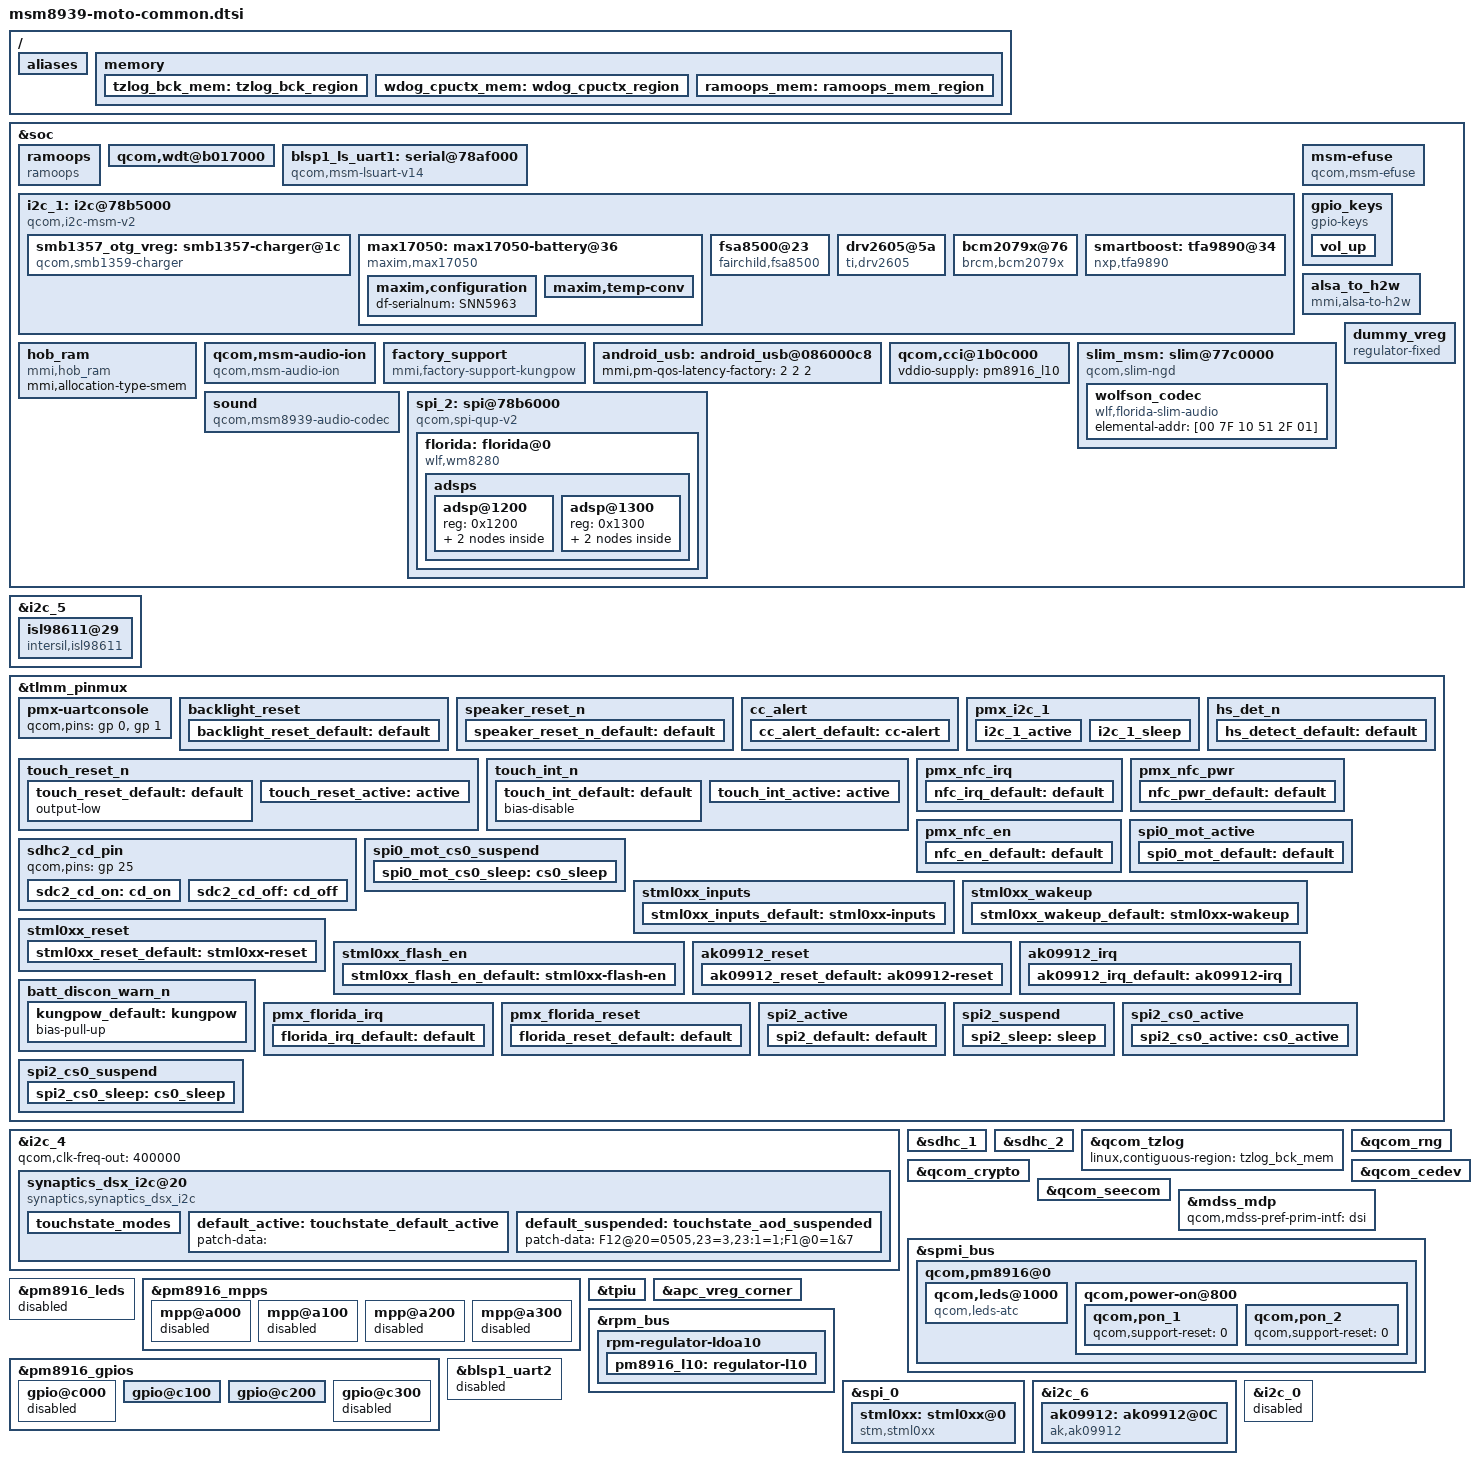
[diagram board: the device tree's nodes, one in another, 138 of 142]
/* Copyright (c) 2014, Motorola Mobility LLC. All rights reserved.
*
* This program is free software; you can redistribute it and/or modify
* it under the terms of the GNU General Public License version 2 and
* only version 2 as published by the Free Software Foundation.
*
* This program is distributed in the hope that it will be useful,
* but WITHOUT ANY WARRANTY; without even the implied warranty of
* MERCHANTABILITY or FITNESS FOR A PARTICULAR PURPOSE.  See the
* GNU General Public License for more details.
*/

#include "msm8939.dtsi"
#include "msm8939-pinctrl.dtsi"
#include "msm8939-camera-sensor-lux.dtsi"
#include "carrier-channel-ids.dtsi"
#include <moto-mem-reserve.h>

/ {
	aliases {
		serial0 = &blsp1_ls_uart1;
		i2c1 = &i2c_1;
		spi2 = &spi_2; /* Audio Codec */
	};
	memory {
		tzlog_bck_mem: tzlog_bck_region {
			linux,reserve-contiguous-region;
			linux,reserve-region;
			linux,remove-completely;
			reg = <0x0 TZLOG_BCK_BASE_8939
				0x0 TZLOG_BCK_SIZE>;
			label = "tzlog_bck_mem";
		};

		wdog_cpuctx_mem: wdog_cpuctx_region {
			linux,reserve-contiguous-region;
			linux,reserve-region;
			linux,remove-completely;
			reg = <0x0 WDOG_CPUCTX_BASE_8939
				0x0 WDOG_CPUCTX_SIZE_8939>;
			label = "wdog_cpuctx_mem";
		};

		ramoops_mem: ramoops_mem_region {
			linux,reserve-contiguous-region;
			linux,reserve-region;
			linux,remove-completely;
			reg = <0x0 0xaf000000 0x0 0x80000>;
			label = "ramoops_mem";
		};
	};
};

&soc {
	ramoops {
		compatible = "ramoops";
		status = "ok";

		android,ramoops-buffer-start = <0xaf000000>;
		android,ramoops-buffer-size = <0x80000>;
		android,ramoops-console-size = <0x40000>;
		android,ramoops-record-size = <0x3F800>;
		android,ramoops-annotate-size = <0x800>;
		android,ramoops-dump-oops = <0x1>;

		linux,contiguous-region = <&ramoops_mem>;
	};

	qcom,wdt@b017000 {
		qcom,bark-time = <22000>;
		linux,contiguous-region = <&wdog_cpuctx_mem>;
	};

	/delete-node/ serial@78af000;
	blsp1_ls_uart1: serial@78af000 {
		compatible = "qcom,msm-lsuart-v14";
		reg = <0x78af000 0x200>;
		interrupts = <0 107 0>;
		status = "ok";
		clocks = <&clock_gcc clk_gcc_blsp1_uart1_apps_clk>,
			 <&clock_gcc clk_gcc_blsp1_ahb_clk>;
		clock-names = "core_clk", "iface_clk";
		pinctrl-names = "default";
		pinctrl-0 = <&uart_console_sleep>;
	};

	i2c_1: i2c@78b5000 { /* BLSP1 QUP1 */
                compatible = "qcom,i2c-msm-v2";
                #address-cells = <1>;
                #size-cells = <0>;
                reg-names = "qup_phys_addr", "bam_phys_addr";
                reg = <0x78b5000 0x600>,
                      <0x7884000 0x23000>;
                interrupt-names = "qup_irq", "bam_irq";
                interrupts = <0 95 0>, <0 238 0>;
                clocks = <&clock_gcc clk_gcc_blsp1_ahb_clk>,
                         <&clock_gcc clk_gcc_blsp1_qup1_i2c_apps_clk>;
                clock-names = "iface_clk", "core_clk";
                qcom,clk-freq-out = <400000>;
                qcom,clk-freq-in  = <19200000>;
                pinctrl-names = "i2c_active", "i2c_sleep";
                pinctrl-0 = <&i2c_1_active>;
                pinctrl-1 = <&i2c_1_sleep>;
                qcom,noise-rjct-scl = <0>;
                qcom,noise-rjct-sda = <0>;
                qcom,bam-pipe-idx-cons = <4>;
                qcom,bam-pipe-idx-prod = <5>;
                qcom,master-id = <86>;
	};

	hob_ram {
		compatible = "mmi,hob_ram";
		mmi,allocation-type-smem;
	};

	msm-efuse {
		compatible = "qcom,msm-efuse";
	};

	/delete-node/ regulator_spk;

	qcom,msm-audio-ion {
		compatible = "qcom,msm-audio-ion";
	};

	gpio_keys {
		compatible = "gpio-keys";
		input-name = "gpio-keys";
		pinctrl-names = "tlmm_gpio_key_active","tlmm_gpio_key_suspend";
		pinctrl-0 = <&gpio_key_active>;
		pinctrl-1 = <&gpio_key_suspend>;

		vol_up {
			label = "volume_up";
			gpios = <&msm_gpio 107 0x1>;
			linux,input-type = <1>;
			linux,code = <115>;
			gpio-key,wakeup;
			debounce-interval = <15>;
		};
	};

	factory_support {
		compatible = "mmi,factory-support-kungpow";
		gpios = <&msm_gpio 89 0x0>, /* GPIOF_OUT_INIT_LOW */
			<&msm_gpio 91 0x1>, /* GPIOF_IN */
			<&msm_gpio 93 0x1>; /* GPIOF_IN */
		gpio-names = "factory_kill_disable",
			"factory_cable_detect",
			"factory_warn";
		pinctrl-names = "default";
		pinctrl-0 = <&kungpow_default>;
	};

	android_usb: android_usb@086000c8 {
		mmi,pm-qos-latency-factory = <2 2 2>;
        };

	qcom,cci@1b0c000 {
		vddio-supply = <&pm8916_l10>;
	};

	alsa_to_h2w {
		compatible = "mmi,alsa-to-h2w";
	};

	/delete-node/ slim@77c0000;
	slim_msm: slim@77c0000 {
		cell-index = <1>;
		compatible = "qcom,slim-ngd";
		reg = <0x77c0000 0x2C000>,
		      <0x7784000 0x2A000>;
		reg-names = "slimbus_physical", "slimbus_bam_physical";
		interrupts = <0 163 0>, <0 180 0>;
		interrupt-names = "slimbus_irq", "slimbus_bam_irq";
		qcom,apps-ch-pipes = <0x600000>;
		qcom,ea-pc = <0x140>;

		wolfson_codec {
			compatible = "wlf,florida-slim-audio";
			elemental-addr = [00 7F 10 51 2F 01];
		};
	};

	dummy_vreg: dummy_vreg {
		compatible = "regulator-fixed";
		status = "ok";
		regulator-name = "dummy_vreg";
		regulator-always-on;
	};

	sound {
		compatible = "qcom,msm8939-audio-codec";
		qcom,model = "msm8939-florida-snd-card";
		qcom,tfa9890-earpiece-gpio = <&msm_gpio 89 0>;
		qcom,tfa9890-stereo;
		qcom,cdc-us-euro-gpios = <&msm_gpio 120 0>;
		qcom,headset-jack-type-NC;

		pinctrl-names = "cdc_slim_lines_act", "cdc_slim_lines_sus";
		pinctrl-0 = <&cdc_slim_lines_act>;
		pinctrl-1 = <&cdc_slim_lines_sus>;

		asoc-platform = <&pcm0>, <&pcm1>, <&voip>, <&voice>,
				<&loopback>, <&compress>, <&hostless>,
				<&afe>, <&lsm>, <&routing>, <&lpa>, <&florida>;
		asoc-platform-names = "msm-pcm-dsp.0", "msm-pcm-dsp.1",
				"msm-voip-dsp", "msm-pcm-voice", "msm-pcm-loopback",
				"msm-compress-dsp", "msm-pcm-hostless", "msm-pcm-afe",
				"msm-lsm-client", "msm-pcm-routing", "msm-pcm-lpa",
				"florida-codec";
		asoc-cpu = <&dai_hdmi>, <&dai_mi2s0>, <&dai_mi2s1>,
				<&dai_mi2s2>, <&dai_mi2s3>, <&sb_0_rx>, <&sb_0_tx>,
				<&sb_1_rx>, <&sb_1_tx>, <&sb_3_rx>, <&sb_3_tx>,
				<&sb_4_rx>, <&sb_4_tx>, <&sb_5_tx>, <&bt_sco_rx>,
				<&bt_sco_tx>, <&int_fm_rx>, <&int_fm_tx>, <&afe_pcm_rx>,
				<&afe_pcm_tx>, <&afe_proxy_rx>, <&afe_proxy_tx>,
				<&incall_record_rx>, <&incall_record_tx>, <&incall_music_rx>,
				<&incall_music_2_rx>;
		asoc-cpu-names = "msm-dai-q6-hdmi.8", "msm-dai-q6-mi2s.0",
				"msm-dai-q6-mi2s.1", "msm-dai-q6-mi2s.2",
				"msm-dai-q6-mi2s.3", "msm-dai-q6-dev.16384",
				"msm-dai-q6-dev.16385", "msm-dai-q6-dev.16386",
				"msm-dai-q6-dev.16387", "msm-dai-q6-dev.16390",
				"msm-dai-q6-dev.16391", "msm-dai-q6-dev.16392",
				"msm-dai-q6-dev.16393", "msm-dai-q6-dev.16395",
				"msm-dai-q6-dev.12288", "msm-dai-q6-dev.12289",
				"msm-dai-q6-dev.12292", "msm-dai-q6-dev.12293",
				"msm-dai-q6-dev.224", "msm-dai-q6-dev.225",
				"msm-dai-q6-dev.241", "msm-dai-q6-dev.240",
				"msm-dai-q6-dev.32771", "msm-dai-q6-dev.32772",
				"msm-dai-q6-dev.32773", "msm-dai-q6-dev.32770";
		asoc-codec = <&stub_codec>;
		asoc-codec-names = "msm-stub-codec.1";
	};

	spi_2: spi@78b6000 { /* BLSP1 QUP2 */
		compatible = "qcom,spi-qup-v2";
		#address-cells = <1>;
		#size-cells = <0>;
		reg-names = "spi_physical", "spi_bam_physical";
		reg = <0x78b6000 0x600>,
			<0x7884000 0x23000>;
		interrupt-names = "spi_irq", "spi_bam_irq";
		interrupts = <0 96 0>, <0 238 0>;
		spi-max-frequency = <48000000>;
		pinctrl-names = "default", "sleep", "cs_default";

		pinctrl-0 = <&spi2_default &spi2_cs0_active>;
		pinctrl-1 = <&spi2_sleep &spi2_cs0_sleep>;

		clocks = <&clock_gcc clk_gcc_blsp1_ahb_clk>,
			<&clock_gcc clk_gcc_blsp1_qup2_spi_apps_clk>;
		clock-names = "iface_clk", "core_clk";
		qcom,infinite-mode = <0>;
		qcom,force-cs;
		qcom,use-bam;
		qcom,use-pinctrl;
		qcom,ver-reg-exists;
		qcom,bam-consumer-pipe-index = <6>;
		qcom,bam-producer-pipe-index = <7>;
		qcom,master-id = <86>;
	};
};

&i2c_5 {
	isl98611@29 {
		compatible = "intersil,isl98611";
		reg = <0x29>;
		status = "okay";
		linux,name = "wled:backlight";
		linux,default-trigger = "bkl-trigger";
		intersil,default-on;
		intersil,vn = <20>;
		intersil,vp = <20>;
		intersil,pfm-value = <0x86>;
		intersil,no-reset;
		intersil,init-level = <255>;
		intersil,dimm-threshold = <0x02>;
		pinctrl-names = "default";
		pinctrl-0 = <&backlight_reset_default>;
	};
};

&tlmm_pinmux {
	pmx-uartconsole {
		qcom,pins = <&gp 0>, <&gp 1>;
	};

	backlight_reset {
		qcom,pins = <&gp 101>;
		qcom,num-grp-pins = <1>;
		qcom,pin-func = <0>;
		label = "backlight_reset";
		backlight_reset_default: default {
			drive-strength = <2>;
			output-high;
		};
	};

	speaker_reset_n {
		qcom,pins = <&gp 37>;
		qcom,num-grp-pins = <1>;
		qcom,pin-func = <0>;
		label = "speaker_reset_n";
		speaker_reset_n_default: default {
			drive-strength = <2>;
			output-high;
		};
	};

	cc_alert {
		qcom,pins = <&gp 49>;
		qcom,num-grp-pins = <1>;
		qcom,pin-func = <0>;
		label = "cc-alert";

		cc_alert_default: cc-alert {
			drive-strength = <2>;
			bias-pull-up;
		};
	};

	pmx_i2c_1 {
		/* CLK, DATA */
		qcom,pins = <&gp 3>, <&gp 2>;
		qcom,num-grp-pins = <2>;
		qcom,pin-func = <3>;
		label = "pmx_i2c_1";

		i2c_1_active: i2c_1_active {
			drive-strength = <2>; /* 2 MA */
			bias-disable;         /* No PULL */
		};

		i2c_1_sleep: i2c_1_sleep {
			drive-strength = <2>; /* 2 MA */
			bias-disable;         /* No PULL */
		};
	};

	/delete-node/ pmx_rd_nfc_int;
	/delete-node/ pmx_nfc_reset;

	touch_reset_n {
		qcom,pins = <&gp 20>;
		qcom,num-grp-pins = <1>;
		qcom,pin-func = <0>;
		label = "touch-reset";

		touch_reset_default: default {
			output-low;
		};

		touch_reset_active: active {
			drive-strength = <2>;
			bias-pull-up; /* pull-up */
		};
	};

	touch_int_n {
		qcom,pins = <&gp 21>;
		qcom,num-grp-pins = <1>;
		qcom,pin-func = <0>;
		label = "touch-int";

		touch_int_default: default {
			bias-disable;
		};

		touch_int_active: active {
			drive-strength = <2>;
			bias-pull-up; /* pull-up */
		};
	};

	hs_det_n {
		qcom,pins = <&gp 69>;
		qcom,num-grp-pins = <1>;
		qcom,pin-func = <0>;
		label = "hs-detect-int";

		hs_detect_default: default {
			drive-strength = <2>;
			bias-pull-up;
		};
	};

	pmx_nfc_irq {
		qcom,pins = <&gp 97>;
		qcom,num-grp-pins = <1>;
		qcom,pin-func = <0>;
		label = "nfc_irq";

		nfc_irq_default: default {
			bias-pull-down;
			drive-strength = <2>;
		};
	};

	pmx_nfc_pwr {
		qcom,pins = <&gp 81>;
		qcom,num-grp-pins = <1>;
		qcom,pin-func = <0>;
		label = "nfc_pwr";

		nfc_pwr_default: default {
			bias-pull-down;
			output-low;
			drive-strength = <2>;
		};
	};

	pmx_nfc_en {
		qcom,pins = <&gp 95>;
		qcom,num-grp-pins = <1>;
		qcom,pin-func = <0>;
		label = "nfc_en";

		nfc_en_default: default {
			bias-pull-down;
			output-low;
			drive-strength = <2>;
		};
	};

	sdhc2_cd_pin {
		qcom,pins = <&gp 25>;
		sdc2_cd_on: cd_on {
			drive-strength = <2>;
			bias-disable;
		};
		sdc2_cd_off: cd_off {
			drive-strength = <2>;
			bias-disable;
		};
	};

	spi0_mot_active {
		/* MOSI, MISO, CLK */
		qcom,pins = <&gp 8>, <&gp 9>, <&gp 11>;
		qcom,num-grp-pins = <3>;
		qcom,pin-func = <1>;
		label = "spi0-mot-active";
		/* active state */
		spi0_mot_default: default {
			drive-strength = <2>; /* 2 MA */
			bias-disable = <0>; /* No PULL */
		};
	};

	spi0_mot_cs0_suspend {
		/* CS */
		qcom,pins = <&gp 10>;
		qcom,num-grp-pins = <1>;
		qcom,pin-func = <0>;
		label = "spi0-mot-cs0-suspend";
		spi0_mot_cs0_sleep: cs0_sleep {
			drive-strength = <2>;
			bias-disable = <0>;
			output-high;
		};
	};

	/* IRQ, WakeIRQ, SPI Data Ack, SPI Ready for Receive */
	stml0xx_inputs {
		qcom,pins = <&gp 51>, <&gp 52>, <&gp 38>, <&gp 13>;
		qcom,num-grp-pins = <4>;
		qcom,pin-func = <0>;
		label = "stml0xx-inputs";

		stml0xx_inputs_default: stml0xx-inputs {
			bias-disable;         /* no pull */
			drive-strength = <2>;
		};
	};

	stml0xx_wakeup {
		qcom,pins = <&gp 116>;
		qcom,num-grp-pins = <1>;
		qcom,pin-func = <0>;
		label = "stml0xx-wakeup";

		stml0xx_wakeup_default: stml0xx-wakeup {
			bias-disable;         /* no pull */
			drive-strength = <2>;
			output-high;
		};
	};

	stml0xx_reset {
		qcom,pins = <&gp 120>;
		qcom,num-grp-pins = <1>;
		qcom,pin-func = <0>;
		label = "stml0xx-reset";

		stml0xx_reset_default: stml0xx-reset {
			bias-disable;         /* no pull */
			drive-strength = <2>;
			output-high;
		};
	};

	stml0xx_flash_en {
		qcom,pins = <&gp 121>;
		qcom,num-grp-pins = <1>;
		qcom,pin-func = <0>;
		label = "stml0xx-flash-en";

		stml0xx_flash_en_default: stml0xx-flash-en {
			bias-disable;         /* no pull */
			drive-strength = <2>;
			output-low;
		};
	};

	ak09912_reset {
		qcom,pins = <&gp 90>;
		qcom,num-grp-pins = <1>;
		qcom,pin-func = <0>;
		label = "ak09912-reset";

		ak09912_reset_default: ak09912-reset {
			bias-disable;
			drive-strength = <2>;
			output-high;
		};
	};

	ak09912_irq {
		qcom,pins = <&gp 50>;
		qcom,num-grp-pins = <1>;
		qcom,pin-func = <0>;
		label = "ak09912-irq";

		ak09912_irq_default: ak09912-irq {
			bias-disable;
			drive-strength = <2>;
		};
	};

	batt_discon_warn_n {
		qcom,pins = <&gp 93>;
		qcom,num-grp-pins = <1>;
		qcom,pin-func = <0>;
		label = "batt-discon-warn-n";

		kungpow_default: kungpow {
			bias-pull-up; /* pull-up */
		};
	};

	pmx_florida_irq {
		qcom,pins = <&gp 98>;
		qcom,num-grp-pins = <1>;
		qcom,pin-func = <0>;
		label = "florida_irq";
		florida_irq_default: default {
			bias-disable;
			drive-strength = <2>;
		};
	};

	pmx_florida_reset {
		qcom,pins = <&gp 31>;
		qcom,num-grp-pins = <1>;
		qcom,pin-func = <0>;
		label = "florida_reset";
		florida_reset_default: default {
			output-high;
			bias-pull-up;
			drive-strength = <2>;
		};
	};

	spi2_active {
		/* MOSI, MISO, CLK */
		qcom,pins = <&gp 4>, <&gp 5>, <&gp 7>;
		qcom,num-grp-pins = <3>;
		qcom,pin-func = <1>;
		label = "spi2-active";
		/* active state */
		 spi2_default: default {
			bias-pull-up;
			drive-strength = <6>; /* 6 MA */
		};
	};

	spi2_suspend {
		/* MOSI, MISO, CLK */
		qcom,pins = <&gp 4>, <&gp 5>, <&gp 7>;
		qcom,num-grp-pins = <3>;
		qcom,pin-func = <1>;
		label = "spi2-suspend";
		/* suspended state */
		spi2_sleep: sleep {
			bias-pull-up;
			drive-strength = <6>; /* 6 MA */
		};
	};

	spi2_cs0_active {
		/* CS */
		qcom,pins = <&gp 6>;
		qcom,num-grp-pins = <1>;
		qcom,pin-func = <1>;
		label = "spi2-cs0-active";
		spi2_cs0_active: cs0_active {
			bias-pull-up;
			drive-strength = <6>; /* 6 MA */
		};
	};

	spi2_cs0_suspend {
		/* CS */
		qcom,pins = <&gp 6>;
		qcom,num-grp-pins = <1>;
		qcom,pin-func = <1>;
		label = "spi2-cs0-suspend";
		spi2_cs0_sleep: cs0_sleep {
			bias-pull-up;
			drive-strength = <6>; /* 6 MA */
		};
	};
};

&i2c_4 {
	qcom,clk-freq-out = <400000>;

	synaptics_dsx_i2c@20 {
		compatible = "synaptics,synaptics_dsx_i2c";
		reg = <0x20>;
		interrupt-parent = <&msm_gpio>;
		interrupts = <21 0>;
		gpios = <&msm_gpio 21 0>, /* IRQ */
			<&msm_gpio 20 0>; /* RESET */
		synaptics,gpio-config;
		pinctrl-names = "default", "active";
		pinctrl-0 = <&touch_reset_active &touch_int_default>;
		pinctrl-1 = <&touch_reset_active &touch_int_active>;
		touchstate_modes {
			touchmode-default = <&default_active &default_suspended>;
		};
		default_active: touchstate_default_active {
			patch-data = "";
		};
		default_suspended: touchstate_aod_suspended {
			patch-data = "F12@20=0505,23=3,23:1=1;F1@0=1&7";
		};
	};
};

&sdhc_1 {
	vdd-supply = <&pm8916_l8>;
	qcom,vdd-voltage-level = <2900000 2900000>;
	qcom,vdd-current-level = <200 400000>;

	vdd-io-supply = <&pm8916_l5>;
	qcom,vdd-io-always-on;
	qcom,vdd-io-lpm-sup;
	qcom,vdd-io-voltage-level = <1800000 1800000>;
	qcom,vdd-io-current-level = <200 60000>;

	pinctrl-names = "active", "sleep";
	pinctrl-0 = <&sdc1_clk_on &sdc1_cmd_on &sdc1_data_on>;
	pinctrl-1 = <&sdc1_clk_off &sdc1_cmd_off &sdc1_data_off>;

	qcom,nonremovable;
	qcom,emmc;

	status = "ok";
};

&sdhc_2 {
	vdd-supply = <&pm8916_l11>;
	qcom,vdd-voltage-level = <2800000 2950000>;
	qcom,vdd-current-level = <15000 400000>;

	vdd-io-supply = <&pm8916_l12>;
	qcom,vdd-io-voltage-level = <1800000 2950000>;
	qcom,vdd-io-current-level = <200 50000>;

	pinctrl-names = "active", "sleep";
	pinctrl-0 = <&sdc2_clk_on &sdc2_cmd_on &sdc2_data_on &sdc2_cd_on>;
	pinctrl-1 = <&sdc2_clk_off &sdc2_cmd_off &sdc2_data_off &sdc2_cd_off>;

	#address-cells = <0>;
	interrupt-parent = <&sdhc_2>;
	interrupts = <0 1 2>;
	#interrupt-cells = <1>;
	interrupt-map-mask = <0xffffffff>;
	interrupt-map = <0 &intc 0 125 0
			1 &intc 0 221 0
			2 &msm_gpio 25 0>;
	interrupt-names = "hc_irq", "pwr_irq", "status_irq";
	cd-gpios = <&msm_gpio 25 0x0>;

	qcom,sd;

	status = "ok";
};

&qcom_tzlog {
	status = "okay";
	linux,contiguous-region = <&tzlog_bck_mem>;
};

&qcom_rng {
	status = "okay";
};

&qcom_crypto {
	status = "okay";
};

&qcom_cedev {
	status = "okay";
};

&qcom_seecom {
	status = "okay";
};

&mdss_mdp {
	qcom,mdss-pref-prim-intf = "dsi";
};

&spmi_bus {
	qcom,pm8916@0 {
		qcom,leds@1000 {
			reg = <0x1000 0x100>;
			compatible = "qcom,leds-atc";
			linux,name = "charging";
			qcom,ctrl-reg = <0x4D>;
		};

		qcom,power-on@800 {
			qcom,pon_1 {
				qcom,support-reset = <0>;
			};
			qcom,pon_2 {
				qcom,support-reset = <0>;
			};
		};
	};

};

&pm8916_leds {
	status = "disabled";
};

&pm8916_mpps {
	mpp@a000 { /* MPP 1 */
		status = "disabled";
	};

	mpp@a100 { /* MPP 2 */
		status = "disabled";
	};

	mpp@a200 { /* MPP 3 */
		status = "disabled";
	};

	mpp@a300 { /* MPP 4 */
		status = "disabled";
	};
};

&pm8916_gpios {
	gpio@c000 { /* GPIO 1 */
		/* Battery UICC Alarm */
		status = "disabled";
	};

	gpio@c100 { /* GPIO 2 */
		/* NFC_CLK_REQ */
		qcom,mode = <0>; /* QPNP_PIN_MODE_DIG_IN */
		qcom,pull = <5>; /* QPNP_PIN_PULL_NO */
		qcom,vin-sel = <2>; /* QPNP_PIN_VIN2 */
		qcom,src-sel = <2>; /* QPNP_PIN_SEL_FUNC_1 */
		qcom,master-en = <1>;
	};

	gpio@c200 { /* GPIO 3 */
		/* WM5110LDO_EN */
		status = "okay";
		qcom,mode = <1>;	/* QPNP_PIN_MODE_DIG_OUT */
		qcom,pull = <5>;	/* QPNP_PIN_PULL_NO */
		qcom,vin-sel = <2>;	/* QPNP_PIN_VIN2 */
		qcom,src-sel = <0>;	/* QPNP_PIN_SEL_FUNC_CONSTANT */
		qcom,master-en = <1>;
		qcom,invert = <1>;	/* Invert to get output HIGH */
	};

	gpio@c300 { /* GPIO 4 */
		/* External regulator control for APC */
		status = "disabled";
	};
};

/* CoreSight */
&tpiu {
	pinctrl-names = "sdcard", "trace", "swduart",
			"swdtrc", "jtag", "spmi";
	/* NIDnT */
	pinctrl-0 = <&qdsd_clk_sdcard &qdsd_cmd_sdcard
		     &qdsd_data0_sdcard &qdsd_data1_sdcard
		     &qdsd_data2_sdcard &qdsd_data3_sdcard>;
	pinctrl-1 = <&qdsd_clk_trace &qdsd_cmd_trace
		     &qdsd_data0_trace &qdsd_data1_trace
		     &qdsd_data2_trace &qdsd_data3_trace>;
	pinctrl-2 = <&qdsd_cmd_swduart &qdsd_data0_swduart
		     &qdsd_data1_swduart &qdsd_data2_swduart
		     &qdsd_data3_swduart>;
	pinctrl-3 = <&qdsd_clk_swdtrc &qdsd_cmd_swdtrc
		     &qdsd_data0_swdtrc &qdsd_data1_swdtrc
		     &qdsd_data2_swdtrc &qdsd_data3_swdtrc>;
	pinctrl-4 = <&qdsd_cmd_jtag &qdsd_data0_jtag
		     &qdsd_data1_jtag &qdsd_data2_jtag
		     &qdsd_data3_jtag>;
	pinctrl-5 = <&qdsd_clk_spmi &qdsd_cmd_spmi
		     &qdsd_data0_spmi &qdsd_data3_spmi>;
};

&apc_vreg_corner {
		qcom,cpr-up-threshold = <0>;
		qcom,cpr-down-threshold = <8>;
};

&i2c_1 {
        smb1357_otg_vreg: smb1357-charger@1c {
                compatible = "qcom,smb1359-charger";
                reg = <0x1c>;

                interrupt-parent = <&msm_gpio>;
		interrupts = <62 8>;
		pinctrl-names = "default";
		pinctrl-0 = <&smb_int_default>;
                qcom,smb135x-adc_tm = <&pm8916_adc_tm>;
                qcom,smb135x-vadc = <&pm8916_vadc>;
                qcom,float-voltage-mv = <4400>;
                qcom,charging-timeout = <1536>;
                qcom,recharge-thresh-mv = <200>;
                qcom,iterm-disabled;
                qcom,aicl-disabled;
                qcom,ir-comp-mv = <100>;
                regulator-name = "smb1357_otg_vreg";
                qcom,soft-vfloat-comp-disabled;
                /* therm-bias-supply = <&pma8084_lvs2>; */
                qcom,thermal-mitigation = <2500>, <2400>, <2300>, <2100>,
                                          <2000>, <1910>, <1800>, <1600>,
                                          <1500>, <1400>, <1200>, <1100>,
                                          <1000>, <900>, <700>, <600>,
                                          <500>, <400>, <300>;
                qcom,bms-psy-name = "max170xx_battery";
                qcom,max-batt-curr-ma = <2600>;
                qcom,ext-temp-volt-mv = <4000>;
                qcom,ext-temp-soc = <65>;
                qcom,low-voltage-uv = <3200000>;
                qcom,max-voltage-uv = <4350000>;
		qcom,stepchg-voltage-mv = <4100>;
		qcom,stepchg-taper-ma = <1800>;
        };

	max17050: max17050-battery@36 {
		compatible = "maxim,max17050";
		reg = <0x36>;
		maxim,rsns-microohm = <10000>;

		interrupt-parent = <&msm_gpio>;
		interrupts = <49 0x0>;
		gpios = <&msm_gpio 49 0x11>; /* GPIOF_DIR_IN|GPIOF_EXPORT */
		gpio-names = "cc-alert";

		maxim,enable_por_init;
		maxim,batt_undervoltage_zero_soc;
		maxim,batt-psy-name = "battery";
		maxim,warm-temp-c = <45>;
		maxim,hot-temp-c = <60>;
		maxim,cool-temp-c = <0>;
		maxim,cold-temp-c = <(-20)>;

		maxim,valrt-threshold = <0xffa0>; /* Vmin 3.2V */
		maxim,df-read-battsn;

		pinctrl-names = "default";
		pinctrl-0 = <&cc_alert_default>;

		maxim,configuration {
			df-serialnum    = "SNN5963";

			/include/ "batterydata-fl40-lg.dtsi"
		};

		maxim,temp-conv {
			start   = /bits/ 16 <(-20)>;    /* in degrees C */
			result  = /bits/ 16 <
				/* 1/10th C "real" temps corresponding start, start + 1, etc. fuel gauge temps in C */
				(-302) (-271) (-246) (-222) (-202) (-180) (-162) (-147) (-129) (-114)   /* -20 C ... -11 C */
				(-101) (-86)  (-72)  (-59)  (-48)  (-35)  (-23)  (-12)  (-2)   10       /* -10 C ... -1  C */
				22     32     42     51     62     72     82     91     99     110      /*  0  C ...  9  C */
				120    129    138    146    156    165    175    184    192    200      /*  10 C ...  19 C */
				210    220    230    238    247    256    266    275    285    294      /*  20 C ...  29 C */
				303    313    324    333    343    353    364    375    385    395      /*  30 C ...  39 C */
				407    419    430    441    453    466    479    492    505    520      /*  40 C ...  49 C */
				534    548    565    581    597    616    635    654    676    697      /*  50 C ...  59 C */
				721    747    775    800                                                /*  60 C ...  63 C */
			>;
		};
	};

	fsa8500@23 {
		compatible = "fairchild,fsa8500";
		reg = <0x23>;
		gpios = <&msm_gpio 69 0x0>;
		pinctrl-names = "default";
		pinctrl-0 = <&hs_detect_default>;
		fsa8500-init-regs = <0x0C 0x41>,
				    <0x0F 0xF9>,
				    <0x11 0x84>,
				    <0x13 0xBF>,
				    <0x14 0x69>;

		fsa8500-keymap = <0x4000000 0xE2>, /* SND_JACK_BTN_0 - KEY_MEDIA */
				 <0x0400000 0x246>, /* SND_JACK_BTN_4 - KEY_VOICECOMMAND */
				 <0x0200000 0x73>, /* SND_JACK_BTN_5 - KEY_VOLUMEUP */
				 <0x0100000 0x72>; /* SND_JACK_BTN_6 - KEY_VOLUMEDOWN */
	};

	/* TI drv2605 */
	drv2605@5a {
		compatible = "ti,drv2605";
		reg = <0x5A>;
		gpios = <&msm_gpio 84 0>;        /* EN_GPIO */
		external_trigger = <2>;
		default_effect = <17>;          /* Strong Click 100% */
		rated_voltage = <0x72>;         /* 2.4v */
		overdrive_voltage = <0xBA>;     /* 3.6v */
	};

	/* BCM 20795 NFC Controller */
	bcm2079x@76 {
		compatible = "brcm,bcm2079x";
		reg = <0x76>;
		interrupt-parent = <&msm_gpio>;
		interrupts = <97 0>; /* NFC_IRQ */
		gpios = <&msm_gpio 95 0>, /* NFC_ENABLE_IN */
			<&msm_gpio 97 0>, /* NFC_IRQ */
			<&msm_gpio 81 0>; /* NFC_POWER_ON */

		pinctrl-names = "default";
		pinctrl-0 = <&nfc_irq_default &nfc_pwr_default &nfc_en_default>;
	};

	/* smart boost */
	smartboost: tfa9890@34 {
		compatible = "nxp,tfa9890";
		reg = <0x34>;
		gpios = <&msm_gpio 37 0>;     /* RESET */
		tfa_vdd-supply = <&pm8916_l6>;
		nxp,tfa_max-vol-steps = <15>;
		nxp,tfa-dev = "left";
		nxp,tfa_pcm-start-delay = <100>;
		/* nxp,tfa9890_bin_path = "lux"; */
	};
};

&rpm_bus {
	rpm-regulator-ldoa10 {
		pm8916_l10: regulator-l10 {
			regulator-min-microvolt = <1800000>;
			regulator-max-microvolt = <1800000>;
			qcom,init-voltage = <1800000>;
		};
	};
};

&spi_0 {
	spi-max-frequency = <8000000>;
	pinctrl-0 = <&spi0_mot_default &spi0_cs0_active>;
	pinctrl-1 = <&spi0_sleep &spi0_mot_cs0_sleep>;

	qcom,use-bam;

	stml0xx: stml0xx@0 {
		compatible = "stm,stml0xx";
		status = "okay";
		reg = <0>;
		spi-max-frequency = <8000000>;
		gpios = <&msm_gpio 51 0>,        /* IRQ */
			<&msm_gpio 120 0>,       /* RESET */
			<&msm_gpio 121 0>,       /* BSLEN */
			<&msm_gpio 52 0>,        /* WakeIRQ */
			<&msm_gpio 13 0>,         /* SPI Ready for Receive */
			<&msm_gpio 38 0>,        /* SPI Data Ack */
			<&msm_gpio 116 0>;       /* Wake Up Sensor Hub */
		lux_table = <5 50 100 1500 3000 8000>;
		brightness_table = <9 14 18 46 67 93 140>;
		bslen_pin_active_value = <1>;
		accel_orientation_1 = <7>;       /* Accel 1  Orientation value */
		accel_orientation_2 = <7>;       /* Accel 2  Orientation value */
		ct406_detect_threshold = <0x00C8>;
		ct406_undetect_threshold = <0x00A5>;
		ct406_recalibrate_threshold = <0x0064>;
		ct406_pulse_count = <0x02>;
		ct406_prox_gain = <0x02>;
		ct406_als_lux1_c0_mult = <0x294>;
		ct406_als_lux1_c1_mult = <0x55A>;
		ct406_als_lux1_div = <0x64>;
		ct406_als_lux2_c0_mult = <0xDA>;
		ct406_als_lux2_c1_mult = <0x186>;
		ct406_als_lux2_div = <0x64>;
		dsp_iface_enable = <1>;
		headset_detect_enable = <0>;
		headset_hw_version = <0>;
		headset_insertion_debounce = <0x01F4>;
		headset_removal_debounce = <0x0080>;
		headset_button_down_debounce = <0x0032>;
		headset_button_up_debounce = <0x0032>;
		headset_button_0-1_threshold = <0x009D>;
		headset_button_1-2_threshold = <0x0145>;
		headset_button_2-3_threshold = <0x0201>;
		headset_button_3-upper_threshold = <0x03B0>;
		headset_button_1_keycode = <0xE2>;  /* KEY_MEDIA        */
		headset_button_2_keycode = <0x246>; /* KEY_VOICECOMMAND */
		headset_button_3_keycode = <0x73>;  /* KEY_VOLUMEUP     */
		headset_button_4_keycode = <0x72>;  /* KEY_VOLUMEDOWN   */
		sensor1-supply = <&pm8916_l6>;
		sensor2-supply = <&pm8916_l17>;
		cover_detect_polarity = <1>;
		reset_hw_type = <0>;
		pinctrl-names = "default";
		pinctrl-0 = <&stml0xx_inputs_default
			     &stml0xx_wakeup_default
			     &stml0xx_reset_default
			     &stml0xx_flash_en_default>;
	};
};

&i2c_6 {
	status = "okay";

	ak09912: ak09912@0C {
		compatible = "ak,ak09912";
		reg = <0x0C>;
		gpios = <&msm_gpio 90 0>, /* RESET */
		        <&msm_gpio 50 0>; /* IRQ */
		pinctrl-names = "default";
		pinctrl-0 = <&ak09912_reset_default &ak09912_irq_default>;
		ak,layout = <6>;
	};
};

&blsp1_uart2 {
	status = "disabled";
};

&i2c_0 {
	status = "disabled";
};

&spi_2 {
	florida: florida@0 {
		compatible = "wlf,wm8280";
		spi-max-frequency = <26000000>;
		spi-cs-low;
		reg = <0x0>;
		interrupt-parent = <&msm_gpio>;
		interrupts = <98 0>;
		irq-base = <800>;
		gpio-base = <200>;
		wlf,reset = <&msm_gpio 31 0>;
		wlf,irq = <&msm_gpio 98 0>;
		wlf,out-mono = <0 1 0 0 0 0>;

		pinctrl-names = "default";
		pinctrl-0 = <&florida_irq_default &florida_reset_default>;

		AVDD-supply = <&pm8916_s4>;
		DCVDD-supply = <&pm8916_l11>;
		DBVDD1-supply = <&pm8916_s4>;
		DBVDD2-supply = <&pm8916_s4>;
		DBVDD3-supply = <&pm8916_s4>;
		CPVDD-supply = <&pm8916_s4>;
		SPKVDDL-supply = <&dummy_vreg>;
		SPKVDDR-supply = <&dummy_vreg>;

		gpio-controller;
		#gpio-cells = <2>;

		gpio-defaults = <0x00002102
				0xffffffff
				0x00010000
				0x00000004
				0xffffffff>;
		adsps {
			#address-cells = <1>;
			#size-cells = <0>;
			adsp@1200 {
				reg = <0x1200>;
				firmware {
					frontend {
						wlf,wmfw-file = "aov-frontend";
						wlf,bin-file = "aov-vrgain";
						wlf,compr-caps = <1 1 4 1 16000>;
					};
				};
			};
			adsp@1300 {
				reg = <0x1300>;
				firmware {
					aov {
						wlf,wmfw-file = "aov-control";
						wlf,bin-file = "aov-model";
						wlf,compr-caps = <1 1 4 1 16000>;
					};
				};
			};
		};
	};
};
